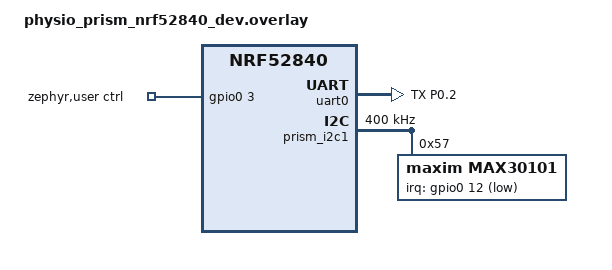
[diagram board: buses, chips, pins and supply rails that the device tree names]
#include <zephyr/dt-bindings/gpio/prism-header.h>

&pinctrl {
	uart0_ppg_i2c1_default: uart0_ppg_i2c1_default {
		group1 {
			psels = <NRF_PSEL(UART_TX, 0, 2)>;
		};
	};

	uart0_ppg_i2c1_sleep: uart0_ppg_i2c1_sleep {
		group1 {
			psels = <NRF_PSEL(UART_TX, 0, 2)>;
			low-power-enable;
		};
	};
};

/ {
	aliases {
		heart-rate-sensor = &max30101;
	};

	zephyr,user {
		ctrl-gpios = <&gpio0 3 GPIO_ACTIVE_HIGH>;
	};
};

&prism_adc{
	status = "disabled";
};

&uart0 {
//	current-speed = <921600>;
	pinctrl-0 = <&uart0_ppg_i2c1_default>;
	pinctrl-1 = <&uart0_ppg_i2c1_sleep>;
};

&prism_i2c1 {

	clock-frequency = < I2C_BITRATE_FAST >;

	max30101: max30101@57 {
		compatible = "maxim,max30101";
		reg = <0x57>;
		acq-mode = "multi-led";
		smp-ave = <8>;
		adc-rge = <2048>;
		smp-sr = <50>;
		led-pw = <69>;
		led-slot = <1 2 3 0>;
		led-pa = [0f 0f 0f];
		fifo-watermark = <12>;
		irq-gpios = <&gpio0 12 GPIO_ACTIVE_LOW>;
	};
};
